# EFR32MG21A010F1024IM32 register map
Vendor: Silicon Labs; Series: EFR32; File version: B
Registers are 32-bit, read-write, reset 0x0 unless marked. A register's access mark holds for its fields unless they carry their own. Offsets are from the block's base; [hi:lo] are bit positions; {n}, {i} and the like mark numbered series.

## BURAM_S — BURAM_S Registers
Base 0x40080000
Same registers: BURAM_NS 0x50080000
{0x0+4i} RET{i}_REG (i=0..31)
  [31:0] RETREG — Latch based Retention register

## GPCRC_S — GPCRC_S Registers
Base 0x40088000
Same registers: GPCRC_NS 0x50088000
0x00 IPVERSION ro
  [31:0] IPVERSION — IP Version ID
0x04 EN
  [0] EN — CRC Enable
    0=DISABLE (Disable CRC function. Reordering functions are still available. Only BITREVERSE and BYTEREVERSE bits are configurable in this mode.); 1=ENABLE (Writes to INPUTDATA registers will result in CRC operations.)
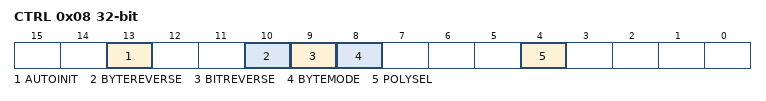
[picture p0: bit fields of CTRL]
0x08 CTRL
  [13] AUTOINIT — Auto Init Enable
  [10] BYTEREVERSE — Byte Reverse Mode
    0=NORMAL (No reverse: B3, B2, B1, B0); 1=REVERSED (Reverse byte order. For 32-bit: B0, B1, B2, B3; For 16-bit: 0, 0, B0, B1)
  [9] BITREVERSE — Byte-level Bit Reverse Enable
    0=NORMAL (No reverse); 1=REVERSED (Reverse bit order in each byte)
  [8] BYTEMODE — Byte Mode Enable
  [4] POLYSEL — Polynomial Select
    0=CRC32 (CRC-32 (0x04C11DB7) polynomial selected); 1=CRC16 (16-bit CRC programmable polynomial selected)
0x0C CMD wo
  [0] INIT — Initialization Enable
0x10 INIT
  [31:0] INIT — CRC Initialization Value
0x14 POLY
  [15:0] POLY — CRC Polynomial Value
0x18 INPUTDATA wo
  [31:0] INPUTDATA — Input Data for 32-bit
0x1C INPUTDATAHWORD wo
  [15:0] INPUTDATAHWORD — Input Data for 16-bit
0x20 INPUTDATABYTE wo
  [7:0] INPUTDATABYTE — Input Data for 8-bit
0x24 DATA ro
  [31:0] DATA — CRC Data Register
0x28 DATAREV ro
  [31:0] DATAREV — Data Reverse Value
0x2C DATABYTEREV ro
  [31:0] DATABYTEREV — Data Byte Reverse Value

## RADIOAES_S — RADIOAES_S Registers
Base 0x44000000
Same registers: RADIOAES_NS 0x54000000
0x00 FETCHADDR — Fetcher: Start address of data block
  [31:0] ADDR — Start address of data block
0x04 FETCHDESCR — Fetcher: Descriptor address (Should be renamed to match Barco doc after PG)
  [31:0] DESCR — Descriptor address
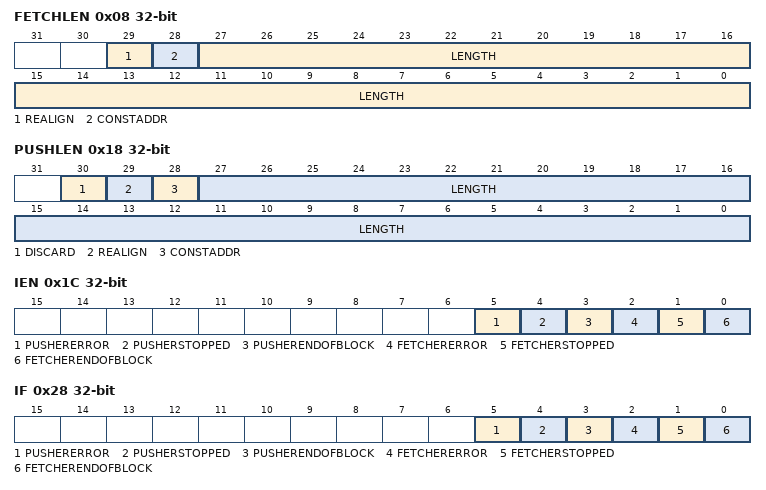
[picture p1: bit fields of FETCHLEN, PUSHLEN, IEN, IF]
0x08 FETCHLEN — Fetcher: Length of data block
  [29] REALIGN — Realign lengh
  [28] CONSTADDR — Constant address
  [27:0] LENGTH — Length of data block
0x0C FETCHTAG — Fetcher: User tag
  [31:0] TAG — User tag
0x10 PUSHADDR — Pusher: Start address of data block
  [31:0] ADDR — Start address of data block
0x14 PUSHDESCR — Pusher: Descriptor address (Should be renamed to match Barco doc after PG)
  [31:0] DESCR — Descriptor address
0x18 PUSHLEN — Pusher: Length of data block
  [30] DISCARD — Discard data
  [29] REALIGN — Realign length
  [28] CONSTADDR — Constant address
  [27:0] LENGTH — Start address of data block
0x1C IEN — Interrupt enable
  [5] PUSHERERROR — Error interrupt enable
  [4] PUSHERSTOPPED — Stopped interrupt enable
  [3] PUSHERENDOFBLOCK — End of block interrupt enable
  [2] FETCHERERROR — Error interrupt enable
  [1] FETCHERSTOPPED — Stopped interrupt enable
  [0] FETCHERENDOFBLOCK — End of block interrupt enable
0x28 IF ro — Interrupt flag register
  [5] PUSHERERROR — Error interrupt flag
  [4] PUSHERSTOPPED — Stopped interrupt flag
  [3] PUSHERENDOFBLOCK — End of block interrupt flag
  [2] FETCHERERROR — Error interrupt flag
  [1] FETCHERSTOPPED — Stopped interrupt flag
  [0] FETCHERENDOFBLOCK — End of block interrupt flag
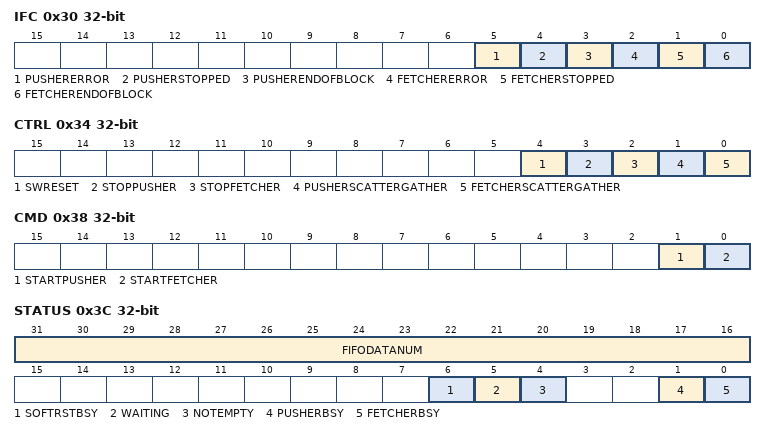
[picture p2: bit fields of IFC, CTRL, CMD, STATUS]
0x30 IFC wo — Writing a '1' clears the interrupt status. Writing a '0' has no effect.
  [5] PUSHERERROR — New BitField
  [4] PUSHERSTOPPED — New BitField
  [3] PUSHERENDOFBLOCK — New BitField
  [2] FETCHERERROR — Error interrupt flag clear
  [1] FETCHERSTOPPED — Stopped interrupt flag clear
  [0] FETCHERENDOFBLOCK — End of block interrupt flag clear
0x34 CTRL — Control register, called CONFIG in Barco datasheet.
  [4] SWRESET — Software reset
  [3] STOPPUSHER
  [2] STOPFETCHER
  [1] PUSHERSCATTERGATHER
  [0] FETCHERSCATTERGATHER
0x38 CMD wo — Command register for starting the fetcher and pusher
  [1] STARTPUSHER — Start push
  [0] STARTFETCHER — Start fetch
0x3C STATUS ro
  [31:16] FIFODATANUM — Number of data in output FIFO
  [6] SOFTRSTBSY — Software reset busy
  [5] WAITING — Pusher waiting for FIFO
  [4] NOTEMPTY — Not empty flag from input FIFO (fetcher)
  [1] PUSHERBSY — Pusher busy
  [0] FETCHERBSY — Fetcher busy
